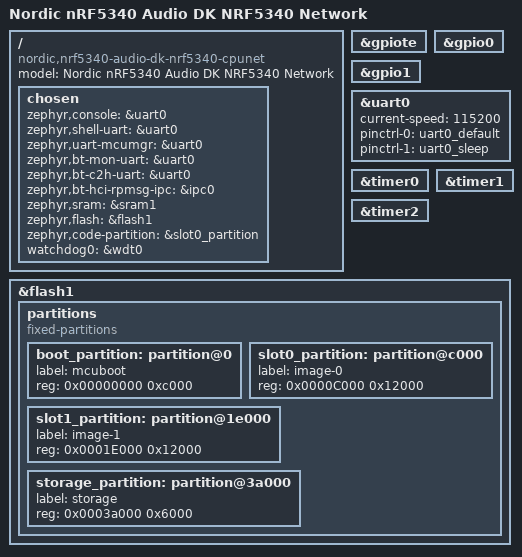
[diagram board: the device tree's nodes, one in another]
/*
 * Copyright (c) 2020 Nordic Semiconductor ASA
 *
 * SPDX-License-Identifier: Apache-2.0
 */

/dts-v1/;
#include <nordic/nrf5340_cpunet_qkaa.dtsi>
#include "nrf5340_audio_dk_nrf5340_cpunet-pinctrl.dtsi"

/ {
	model = "Nordic nRF5340 Audio DK NRF5340 Network";
	compatible = "nordic,nrf5340-audio-dk-nrf5340-cpunet";

	chosen {
		zephyr,console = &uart0;
		zephyr,shell-uart = &uart0;
		zephyr,uart-mcumgr = &uart0;
		zephyr,bt-mon-uart = &uart0;
		zephyr,bt-c2h-uart = &uart0;
		zephyr,bt-hci-rpmsg-ipc = &ipc0;
		zephyr,sram = &sram1;
		zephyr,flash = &flash1;
		zephyr,code-partition = &slot0_partition;
		watchdog0 = &wdt0;
	};
};

&gpiote {
	status = "okay";
};

&gpio0 {
	status = "okay";
};

&gpio1 {
	status = "okay";
};

&uart0 {
	status = "okay";
	current-speed = <115200>;
	pinctrl-0 = <&uart0_default>;
	pinctrl-1 = <&uart0_sleep>;
	pinctrl-names = "default", "sleep";
};

&timer0 {
	status = "okay";
};

&timer1 {
	status = "okay";
};

&timer2 {
	status = "okay";
};

&flash1 {

	partitions {
		compatible = "fixed-partitions";
		#address-cells = <1>;
		#size-cells = <1>;

		boot_partition: partition@0 {
			label = "mcuboot";
			reg = <0x00000000 0xc000>;
		};
		slot0_partition: partition@c000 {
			label = "image-0";
			reg = <0x0000C000 0x12000>;
		};
		slot1_partition: partition@1e000 {
			label = "image-1";
			reg = <0x0001E000 0x12000>;
		};
		storage_partition: partition@3a000 {
			label = "storage";
			reg = <0x0003a000 0x6000>;
		};
	};
};

/* Include shared RAM configuration file */
#include "nrf5340_audio_dk_nrf5340_shared_sram_planning_conf.dtsi"
#include "nrf5340_audio_dk_nrf5340_shared.dtsi"
